# PSRAM0_FW register map
Vendor: Texas Instruments
Peripheral module from a debugger description file (folder am65x).
Registers are 32-bit, read-write, no defined reset value unless marked. A register's access mark holds for its fields unless they carry their own. Offsets are as the file gives them; lines under a group give offsets from that group; [hi:lo] are bit positions; {n}, {i} and the like mark numbered series; 'fields as' and 'values as' point back to an identical list; <NAME> marks a mode.

## PSRAM0_FW
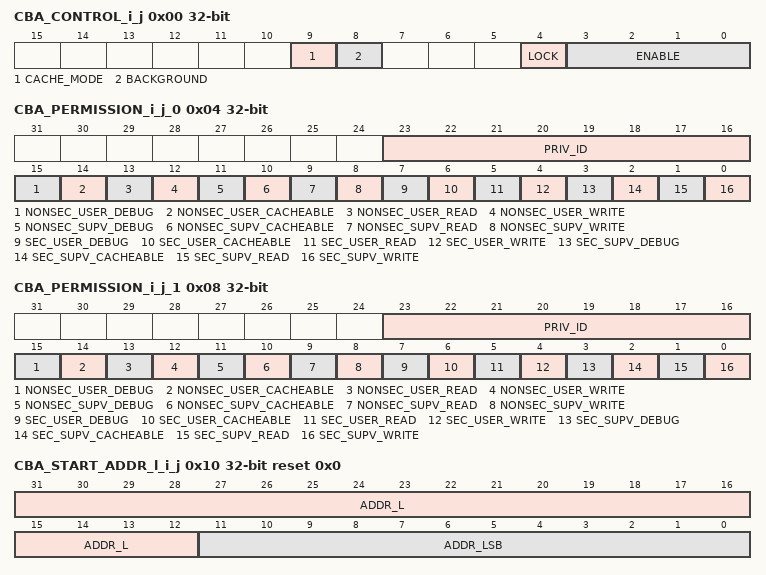
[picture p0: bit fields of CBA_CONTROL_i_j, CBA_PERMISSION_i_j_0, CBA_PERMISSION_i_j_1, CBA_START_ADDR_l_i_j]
0x00 CBA_CONTROL_i_j — The Firewall i Region j Control Register defines the control fields for the firewall. Offset = 0h + (i * 400h) + (j * 20h), where: i = 0h to 7Fh, j = 0h to 1Fh
  [9] CACHE_MODE — Cache mode for region.Set to 1 to check cache permissions. Set to 0 to ignore cache permissions.
  [8] BACKGROUND — Background enable for region.There can be 1 backgroun region per FW and foreground regions can have overlapping addresses only with the background region.
  [4] LOCK — Lock region.Once set region values cannot be modified.
  [3:0] ENABLE — Enable region.A value of 0xA enables, others disable.
0x04 CBA_PERMISSION_i_j_0 — The Firewall i Region j Permission 0 to Permission 2 Registers define the permissions for the firewall. Offset = 4h + (i * 400h) + (j * 20h), where: i = 0h to 7Fh, j = 0h to 1Fh
  [23:16] PRIV_ID — Allowed privid.
  [15] NONSEC_USER_DEBUG — Non-secure user debug allowed.
  [14] NONSEC_USER_CACHEABLE — Non-secure user cacheable allowed.
  [13] NONSEC_USER_READ — Non-secure user read allowed.
  [12] NONSEC_USER_WRITE — Non-secure user write allowed.
  [11] NONSEC_SUPV_DEBUG — Non-secure supervisor debug allowed.
  [10] NONSEC_SUPV_CACHEABLE — Non-secure supervisor cacheable allowed.
  [9] NONSEC_SUPV_READ — Non-secure supervisor read allowed.
  [8] NONSEC_SUPV_WRITE — Non-secure supervisor write allowed.
  [7] SEC_USER_DEBUG — Secure user debug allowed.
  [6] SEC_USER_CACHEABLE — Secure user cacheable allowed.
  [5] SEC_USER_READ — Secure user read allowed.
  [4] SEC_USER_WRITE — Secure user write allowed.
  [3] SEC_SUPV_DEBUG — Secure supervisor debug allowed.
  [2] SEC_SUPV_CACHEABLE — Secure supervisor cacheable allowed.
  [1] SEC_SUPV_READ — Secure supervisor read allowed.
  [0] SEC_SUPV_WRITE — Secure supervisor write allowed.
0x08 CBA_PERMISSION_i_j_1 — The Firewall i Region j Permission 0 to Permission 2 Registers define the permissions for the firewall. Offset = 4h + (i * 400h) + (j * 20h), where: i = 0h to 7Fh, j = 0h to 1Fh
  fields as CBA_PERMISSION_i_j_0
0x10 CBA_START_ADDR_l_i_j access per field reset 0x0 (reset mask 0xFFF) — The Firewall i Region j Start Address Low Register defines the start address bits 31 to 0 for the firewall. Offset = 10h + (i * 400h) + (j * 20h), where: i = 0h to 7Fh, j = 0h to 1Fh
  [31:12] ADDR_L rw — Start address bits 31 to 12.Lowest 12 bits are forced to 0 as address must be 4KB aligned.
  [11:0] ADDR_LSB ro — Start address bits 11 to 0 are forced to 0 as address must be 4KB aligned.
0x14 CBA_START_ADDR_H_i_j — The Firewall i Region j Start Address High Register defines the start address bits 47 to 32 for the firewall. Offset = 14h + (i * 400h) + (j * 20h), where: i = 0h to 7Fh, j = 0h to 1Fh
  [15:0] ADDR_H — Start address bits 47 to 32.
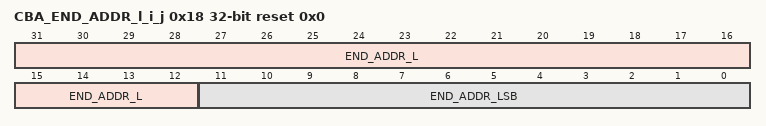
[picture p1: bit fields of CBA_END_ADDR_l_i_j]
0x18 CBA_END_ADDR_l_i_j access per field reset 0x0 (reset mask 0xFFF) — The Firewall i Region j End Address Low Register defines the end address bits 31 to 0 to include for the firewall. Offset = 18h + (i * 400h) + (j * 20h), where: i = 0h to 7Fh, j = 0h to 1Fh
  [31:12] END_ADDR_L rw — End address bits 31 to 12 to include in the match.Lowest 12 bits are forced to 1s as address must be 4KB aligned.
  [11:0] END_ADDR_LSB ro — End address bits 11 to 0 are forced to 1s as address must be 4KB aligned minus 1.
0x1C CBA_END_ADDR_H_i_j — The Firewall i Region j End Address High Register defines the end address bits 47 to 32 to include for the firewall. Offset = 1Ch + (i * 400h) + (j * 20h), where: i = 0h to 7Fh, j = 0h to 1Fh
  [15:0] END_ADDR_H — End address bits 47 to 32 to include in the match.
